# LPC1102_04 register map
File version: 4
CPU: CM0 r0p0, little endian, no MPU, no FPU, 0x2 interrupt priority bits, 0x0 interrupts
Registers are 32-bit, read-write, reset 0x0 unless marked. A register's access mark holds for its fields unless they carry their own. Offsets are from the block's base; [hi:lo] are bit positions; {n}, {i} and the like mark numbered series.

## CT16B0 — 16-bitcounter/timers (CT16B0/1)
Base 0x4000C000
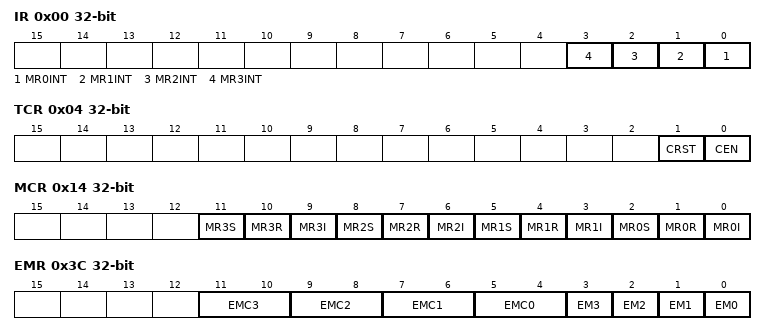
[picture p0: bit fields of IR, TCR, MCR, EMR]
0x00 IR — Interrupt Register (IR). The IR can be written to clear interrupts. The IR can be read to identify which of five possible interrupt sources are pending.
  [n] MR{n}INT (n=0..3) — Interrupt flag for match channel {n}.
0x04 TCR — Timer Control Register (TCR). The TCR is used to control the Timer Counter functions. The Timer Counter can be disabled or reset through the TCR.
  [1] CRST — When one, the Timer Counter and the Prescale Counter are synchronously reset on the next positive edge of PCLK. The counters remain reset until TCR[1] is returned to zero.
  [0] CEN — When one, the Timer Counter and Prescale Counter are enabled for counting. When zero, the counters are disabled.
0x08 TC — Timer Counter (TC). The 16-bit TC is incremented every PR+1 cycles of PCLK. The TC is controlled through the TCR.
  [15:0] TC — Timer counter value.
0x0C PR — Prescale Register (PR). When the Prescale Counter (below) is equal to this value, the next clock increments the TC and clears the PC.
  [15:0] PR — Prescale counter max value.
0x10 PC — Prescale Counter (PC). The 16-bit PC is a counter which is incremented to the value stored in PR. When the value in PR is reached, the TC is incremented and the PC is cleared. The PC is observable and controllable through the bus interface.
  [15:0] PC — prescale counter value.
0x14 MCR — Match Control Register (MCR). The MCR is used to control if an interrupt is generated and if the TC is reset when a Match occurs.
  [all] fields
    1=Enabled; 0=Disabled
  [3n+2] MR{n}S (n=0..3) — Stop on MR{n}: the TC and PC will be stopped and TCR[0] will be set to 0 if MR{n} matches the TC.
  [3n+1] MR{n}R (n=0..3) — Reset on MR{n}: the TC will be reset if MR{n} matches it.
  [3n] MR{n}I (n=0..3) — Interrupt on MR{n}: an interrupt is generated when MR{n} matches the value in the TC.
{0x18+4i} MR{i} (i=0..3) — Match Register. MR can be enabled through the MCR to reset the TC, stop both the TC and PC, and/or generate aninterrupt every time MR matches the TC.
  [15:0] MATCH — Timer counter match value.
0x3C EMR — External Match Register (EMR). The EMR controls the match function and the external match pins CT16B0_MAT[2:0].
  [2n+5:2n+4] EMC{n} (n=0..3) — External Match Control {n}. Determines the functionality of External Match {n}.
    0=DONOTHING; 1=CLEAR (Clear the corresponding External Match bit/output to 0 (CT16Bn_MATm pin is LOW if pinned out).); 2=SET (Set the corresponding External Match bit/output to 1 (CT16Bn_MATm pin is HIGH if pinned out).); 3=TOGGLE (Toggle the corresponding External Match bit/output.)
  [3] EM3 — External Match 3. This bit reflects the state of output of match channel 3. When a match occurs between the TC and MR3, this bit can either toggle, go LOW, go HIGH, or do nothing. Bits EMR[11:10] control the functionality of this output. There is no output pin available for this channel on either of the 16-bit timers.
  [2] EM2 — External Match 2. This bit reflects the state of output match channel 2, whether or not this output is connected to its pin. When a match occurs between the TC and MR2, this bit can either toggle, go LOW, go HIGH, or do nothing. Bits EMR[9:8] control the functionality of this output. Note that on counter/timer 0 this match channel is not pinned out. This bit is driven to the CT16B1_MAT2 pin if the match function is selected in the IOCON registers (0 = LOW, 1 = HIGH).
  [1] EM1 — External Match 1. This bit reflects the state of output CT16B0_MAT1/CT16B1_MAT1, whether or not this output is connected to its pin. When a match occurs between the TC and MR1, this bit can either toggle, go LOW, go HIGH, or do nothing. Bits EMR[7:6] control the functionality of this output. This bit is driven to the CT16B0_MAT1/CT16B1_MAT1 pins if the match function is selected in the IOCON registers (0 = LOW, 1 = HIGH).
  [0] EM0 — External Match 0. This bit reflects the state of output CT16B0_MAT0/CT16B1_MAT0, whether or not this output is connected to its pin. When a match occurs between the TC and MR0, this bit can either toggle, go LOW, go HIGH, or do nothing. Bits EMR[5:4] control the functionality of this output. This bit is driven to the CT16B0_MAT0/CT16B1_MAT0 pins if the match function is selected in the IOCON registers (0 = LOW, 1 = HIGH).
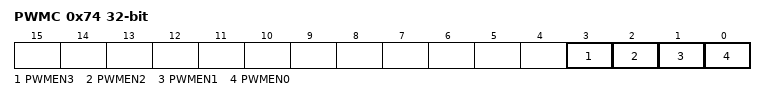
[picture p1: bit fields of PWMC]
0x74 PWMC — PWM Control Register (PWMCON). The PWMCON enables PWM mode for the external match pins CT16B0_MAT[2:0].
  [3] PWMEN3 — When one, PWM mode is enabled for match channel 3. When zero, match channel 3 is controlled by EM3. Note: It is recommended to use to set the PWM cycle because it is not pinned out.
  [2] PWMEN2 — When one, PWM mode is enabled for match channel 2 or pin CT16B0_MAT2. When zero, match channel 2 or pin CT16B0_MAT2 is controlled by EM2. Match channel 2 is not pinned out on timer 1.
  [1] PWMEN1 — When one, PWM mode is enabled for CT16Bn_MAT1. When zero, CT16Bn_MAT1 is controlled by EM1.
  [0] PWMEN0 — When one, PWM mode is enabled for CT16Bn_MAT0. When zero, CT16Bn_MAT0 is controlled by EM0.
